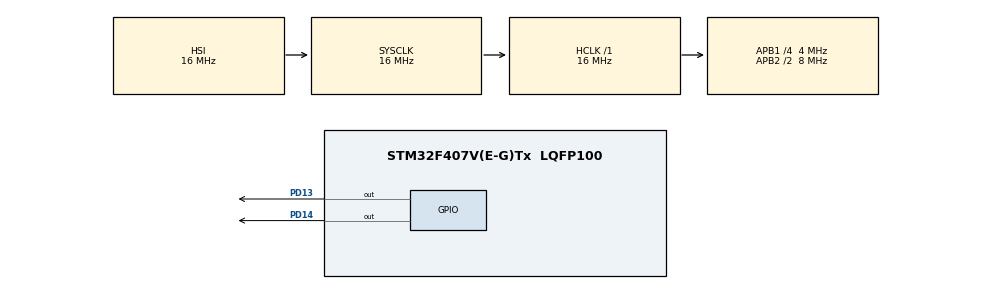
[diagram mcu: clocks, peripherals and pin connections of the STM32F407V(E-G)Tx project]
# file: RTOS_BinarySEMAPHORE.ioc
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FREERTOS.BinarySemaphores01=BinarySema,Dynamic,NULL,Available
FREERTOS.Tasks01=Task_send,0,128,StartSendTask,Default,NULL,Dynamic,NULL,NULL;Task_receive,-3,128,ReceiveTask,Default,NULL,Dynamic,NULL,NULL
Mcu.Family=STM32F4
Mcu.Name=STM32F407V(E-G)Tx
Mcu.Package=LQFP100
NVIC.PriorityGroup=NVIC_PRIORITYGROUP_4
NVIC.TIM2_IRQn=true\:0\:0\:false\:false\:true\:false\:false\:true\:true
NVIC.TimeBase=TIM2_IRQn
NVIC.TimeBaseIP=TIM2
PD13.Signal=GPIO_Output
PD14.Signal=GPIO_Output
ProjectManager.HeapSize=0x200
ProjectManager.StackSize=0x400
ProjectManager.TargetToolchain=STM32CubeIDE
RCC.48MHZClocksFreq_Value=96000000
RCC.AHBFreq_Value=16000000
RCC.APB1CLKDivider=RCC_HCLK_DIV4
RCC.APB1Freq_Value=4000000
RCC.APB1TimFreq_Value=8000000
RCC.APB2CLKDivider=RCC_HCLK_DIV2
RCC.APB2Freq_Value=8000000
RCC.APB2TimFreq_Value=16000000
RCC.CortexFreq_Value=16000000
RCC.HCLKFreq_Value=16000000
RCC.HSE_VALUE=8000000
RCC.HSI_VALUE=16000000
RCC.PLLM=8
RCC.PLLN=336
RCC.PLLQ=7
RCC.SYSCLKFreq_VALUE=16000000
RCC.VCOOutputFreq_Value=672000000
VP_FREERTOS_VS_CMSIS_V1.Mode=CMSIS_V1
VP_SYS_VS_tim2.Mode=TIM2
board=STM32F407G-DISC1

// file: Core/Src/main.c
/* USER CODE BEGIN Header */
/**
  ******************************************************************************
  * @file           : main.c
  * @brief          : Main program body
  ******************************************************************************
  * @attention
  *
  * Copyright (c) 2026 STMicroelectronics.
  * All rights reserved.
  *
  * This software is licensed under terms that can be found in the LICENSE file
  * in the root directory of this software component.
  * If no LICENSE file comes with this software, it is provided AS-IS.
  *
  ******************************************************************************
  */
/* USER CODE END Header */
#include "main.h"
#include "cmsis_os.h"

osThreadId Task_sendHandle;
osThreadId Task_receiveHandle;
osSemaphoreId BinarySemaHandle;

void SystemClock_Config(void);
static void MX_GPIO_Init(void);
void StartSendTask(void const * argument);
void ReceiveTask(void const * argument);

int main(void)
{

  /* MCU Configuration--------------------------------------------------------*/

  /* Reset of all peripherals, Initializes the Flash interface and the Systick. */
  HAL_Init();

  /* Configure the system clock */
  SystemClock_Config();

  /* Initialize all configured peripherals */
  MX_GPIO_Init();

  /* Create the semaphores(s) */
  /* definition and creation of BinarySema */
  osSemaphoreDef(BinarySema);
  BinarySemaHandle = osSemaphoreCreate(osSemaphore(BinarySema), 1);

  /* Create the thread(s) */
  /* definition and creation of Task_send */
  osThreadDef(Task_send, StartSendTask, osPriorityNormal, 0, 128);
  Task_sendHandle = osThreadCreate(osThread(Task_send), NULL);

  /* definition and creation of Task_receive */
  osThreadDef(Task_receive, ReceiveTask, osPriorityIdle, 0, 128);
  Task_receiveHandle = osThreadCreate(osThread(Task_receive), NULL);

  /* Start scheduler */
  osKernelStart();

  /* We should never get here as control is now taken by the scheduler */

  /* Infinite loop */
  while (1)
  {

  }
}

void SystemClock_Config(void)
{
  RCC_OscInitTypeDef RCC_OscInitStruct = {0};
  RCC_ClkInitTypeDef RCC_ClkInitStruct = {0};

  /** Configure the main internal regulator output voltage
  */
  __HAL_RCC_PWR_CLK_ENABLE();
  __HAL_PWR_VOLTAGESCALING_CONFIG(PWR_REGULATOR_VOLTAGE_SCALE1);

  /** Initializes the RCC Oscillators according to the specified parameters
  * in the RCC_OscInitTypeDef structure.
  */
  RCC_OscInitStruct.OscillatorType = RCC_OSCILLATORTYPE_HSI;
  RCC_OscInitStruct.HSIState = RCC_HSI_ON;
  RCC_OscInitStruct.HSICalibrationValue = RCC_HSICALIBRATION_DEFAULT;
  RCC_OscInitStruct.PLL.PLLState = RCC_PLL_NONE;
  if (HAL_RCC_OscConfig(&RCC_OscInitStruct) != HAL_OK)
  {
    Error_Handler();
  }

  /** Initializes the CPU, AHB and APB buses clocks
  */
  RCC_ClkInitStruct.ClockType = RCC_CLOCKTYPE_HCLK|RCC_CLOCKTYPE_SYSCLK
                              |RCC_CLOCKTYPE_PCLK1|RCC_CLOCKTYPE_PCLK2;
  RCC_ClkInitStruct.SYSCLKSource = RCC_SYSCLKSOURCE_HSI;
  RCC_ClkInitStruct.AHBCLKDivider = RCC_SYSCLK_DIV1;
  RCC_ClkInitStruct.APB1CLKDivider = RCC_HCLK_DIV4;
  RCC_ClkInitStruct.APB2CLKDivider = RCC_HCLK_DIV2;

  if (HAL_RCC_ClockConfig(&RCC_ClkInitStruct, FLASH_LATENCY_0) != HAL_OK)
  {
    Error_Handler();
  }
}

static void MX_GPIO_Init(void)
{
  GPIO_InitTypeDef GPIO_InitStruct = {0};

  /* GPIO Ports Clock Enable */
  __HAL_RCC_GPIOD_CLK_ENABLE();

  /*Configure GPIO pin Output Level */
  HAL_GPIO_WritePin(GPIOD, GPIO_PIN_13|GPIO_PIN_14, GPIO_PIN_RESET);

  /*Configure GPIO pins : PD13 PD14 */
  GPIO_InitStruct.Pin = GPIO_PIN_13|GPIO_PIN_14;
  GPIO_InitStruct.Mode = GPIO_MODE_OUTPUT_PP;
  GPIO_InitStruct.Pull = GPIO_NOPULL;
  GPIO_InitStruct.Speed = GPIO_SPEED_FREQ_LOW;
  HAL_GPIO_Init(GPIOD, &GPIO_InitStruct);

}

void StartSendTask(void const * argument)
{
  /* USER CODE BEGIN 5 */
  /* Infinite loop */
  for(;;)
  {
	  osSemaphoreRelease(BinarySemaHandle);
      osDelay(1000);
  }
  /* USER CODE END 5 */
}

void ReceiveTask(void const * argument)
{
  /* USER CODE BEGIN ReceiveTask */
  /* Infinite loop */
  for(;;)
  {
	  osSemaphoreWait(BinarySemaHandle, osWaitForever);
	  HAL_GPIO_TogglePin(GPIOD,GPIO_PIN_14);
	  HAL_GPIO_TogglePin(GPIOD,GPIO_PIN_13);

  }
  /* USER CODE END ReceiveTask */
}

void HAL_TIM_PeriodElapsedCallback(TIM_HandleTypeDef *htim)
{
  if (htim->Instance == TIM2)
  {
    HAL_IncTick();
  }
}

void Error_Handler(void)
{
  __disable_irq();
  while (1)
  {
  }
}
